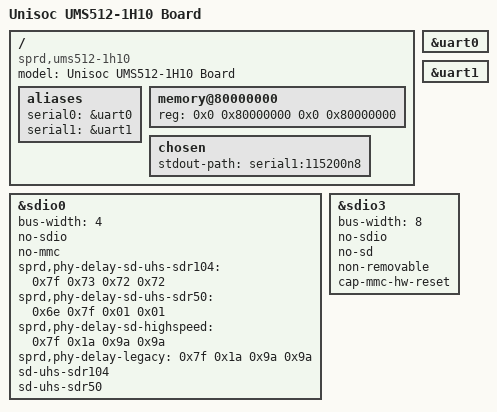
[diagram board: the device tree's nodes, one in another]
// SPDX-License-Identifier: (GPL-2.0 OR MIT)
/*
 * Unisoc UMS512-1h10 boards DTS file
 *
 * Copyright (C) 2021, Unisoc Inc.
 */

/dts-v1/;

#include "ums512.dtsi"

/ {
	model = "Unisoc UMS512-1H10 Board";

	compatible = "sprd,ums512-1h10", "sprd,ums512";

	aliases {
		serial0 = &uart0;
		serial1 = &uart1;
	};

	memory@80000000 {
		device_type = "memory";
		reg = <0x0 0x80000000 0x0 0x80000000>;
	};

	chosen {
		stdout-path = "serial1:115200n8";
	};
};

&uart0 {
	status = "okay";
};

&uart1 {
	status = "okay";
};

/* SD card */
&sdio0 {
	bus-width = <4>;
	no-sdio;
	no-mmc;
	sprd,phy-delay-sd-uhs-sdr104 = <0x7f 0x73 0x72 0x72>;
	sprd,phy-delay-sd-uhs-sdr50 = <0x6e 0x7f 0x01 0x01>;
	sprd,phy-delay-sd-highspeed = <0x7f 0x1a 0x9a 0x9a>;
	sprd,phy-delay-legacy = <0x7f 0x1a 0x9a 0x9a>;
	sd-uhs-sdr104;
	sd-uhs-sdr50;
};

/* EMMC storage */
&sdio3 {
	status = "okay";
	bus-width = <8>;
	no-sdio;
	no-sd;
	non-removable;
	cap-mmc-hw-reset;
};
